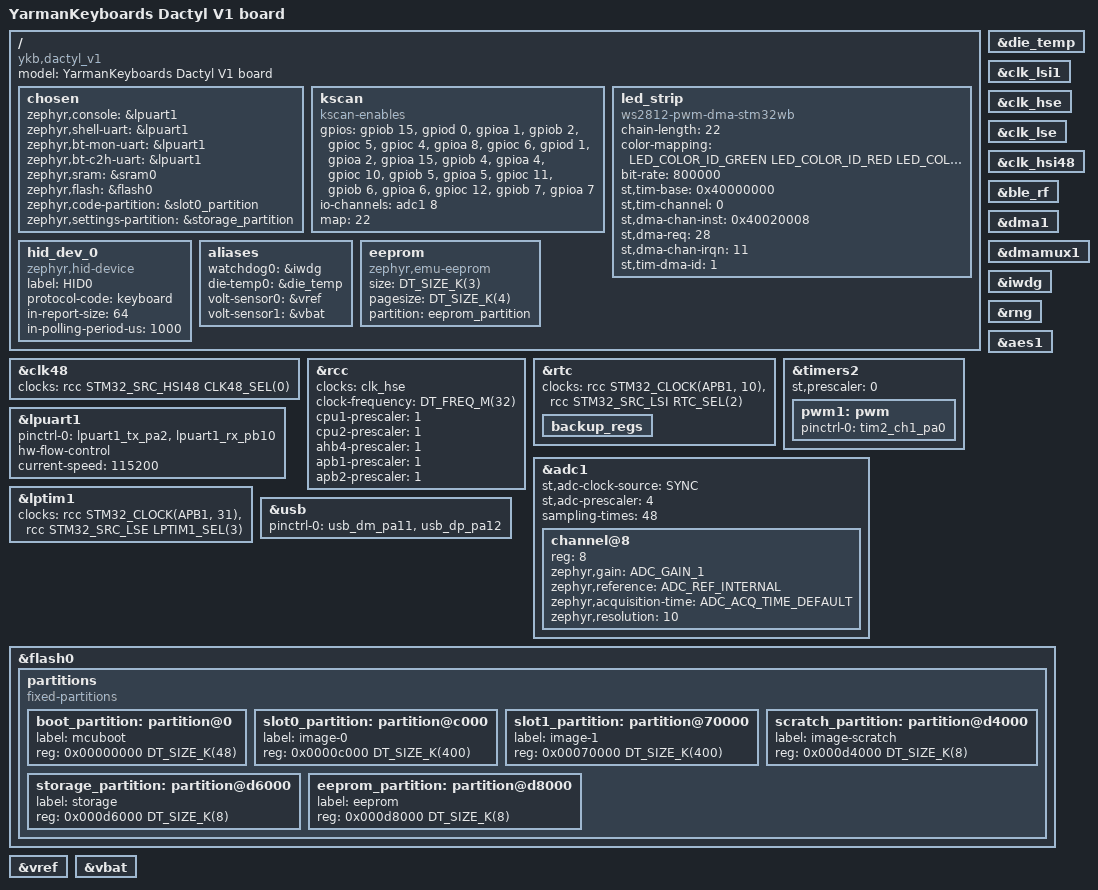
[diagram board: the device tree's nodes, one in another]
/dts-v1/;
#include <st/wb/stm32wb55Xg.dtsi>
#include <st/wb/stm32wb55rgvx-pinctrl.dtsi>
#include <zephyr/dt-bindings/input/input-event-codes.h>
#include <zephyr/dt-bindings/led/led.h>

/ {
	model = "YarmanKeyboards Dactyl V1 board";
	compatible = "ykb,dactyl_v1";

	chosen {
		zephyr,console = &lpuart1;
		zephyr,shell-uart = &lpuart1;
		zephyr,bt-mon-uart = &lpuart1;
		zephyr,bt-c2h-uart = &lpuart1;
		zephyr,sram = &sram0;
		zephyr,flash = &flash0;
		zephyr,code-partition = &slot0_partition;
        zephyr,settings-partition = &storage_partition;

        // ykb,backlight = &led_strip;
	};

    kscan: kscan {
        compatible = "kscan-enables";
        status = "okay";

        gpios = <&gpiob 15 GPIO_ACTIVE_HIGH>,
                <&gpiod 0 GPIO_ACTIVE_HIGH>,
                <&gpioa 1 GPIO_ACTIVE_HIGH>,
                <&gpiob 2 GPIO_ACTIVE_HIGH>,
                <&gpioc 5 GPIO_ACTIVE_HIGH>,
                <&gpioc 4 GPIO_ACTIVE_HIGH>,
                <&gpioa 8 GPIO_ACTIVE_HIGH>,
                <&gpioc 6 GPIO_ACTIVE_HIGH>,
                <&gpiod 1 GPIO_ACTIVE_HIGH>,
                <&gpioa 2 GPIO_ACTIVE_HIGH>,
                <&gpioa 15 GPIO_ACTIVE_HIGH>,
                <&gpiob 4 GPIO_ACTIVE_HIGH>,
                <&gpioa 4 GPIO_ACTIVE_HIGH>,
                <&gpioc 10 GPIO_ACTIVE_HIGH>,
                <&gpiob 5 GPIO_ACTIVE_HIGH>,
                <&gpioa 5 GPIO_ACTIVE_HIGH>,
                <&gpioc 11 GPIO_ACTIVE_HIGH>,
                <&gpiob 6 GPIO_ACTIVE_HIGH>,
                <&gpioa 6 GPIO_ACTIVE_HIGH>,
                <&gpioc 12 GPIO_ACTIVE_HIGH>,
                <&gpiob 7 GPIO_ACTIVE_HIGH>,
                <&gpioa 7 GPIO_ACTIVE_HIGH>;

        io-channels = <&adc1 8>;

        map = <22>;
    };

    led_strip: led_strip {
        compatible = "ws2812-pwm-dma-stm32wb";

        chain-length = <22>;
        color-mapping = <LED_COLOR_ID_GREEN
                         LED_COLOR_ID_RED
                         LED_COLOR_ID_BLUE>;

        bit-rate = <800000>; // 800Khz

        st,tim-base      = <0x40000000>;  // TIM2 base
        st,tim-channel   = <0>;           // TIM_CHANNEL_1
        st,dma-chan-inst = <0x40020008>;  // DMA1_Channel1 base
        st,dma-req       = <28>;          // TIM2_CH1_REQ
        st,dma-chan-irqn = <11>;          // DMA1_Channel1_IRQn
        st,tim-dma-id    = <1>;           // TIM_DMA_ID_CC1
    };

	hid_dev_0: hid_dev_0 {
		compatible = "zephyr,hid-device";
		label = "HID0";
		protocol-code = "keyboard";
		in-report-size = <64>;
		in-polling-period-us = <1000>;
	};

	aliases {
		watchdog0 = &iwdg;
		die-temp0 = &die_temp;
		volt-sensor0 = &vref;
		volt-sensor1 = &vbat;
	};

    eeprom: eeprom {
        compatible = "zephyr,emu-eeprom";
        size = <DT_SIZE_K(3)>;
        pagesize = <DT_SIZE_K(4)>;
        partition = <&eeprom_partition>;
    };
};

&die_temp {
	status = "okay";
};

&clk_lsi1 {
	status = "okay";
};

&clk_hse {
	status = "okay";
};

&clk_lse {
	status = "okay";
};

&clk_hsi48 {
	status = "okay";
};

&clk48 {
	/* Node is disabled by default as default source is HSI48 */
	/* To select another clock, enable the node */
	clocks = <&rcc STM32_SRC_HSI48 CLK48_SEL(0)>;
};

&ble_rf {
    status = "okay";
};

&rcc {
	clocks = <&clk_hse>;
	clock-frequency = <DT_FREQ_M(32)>;
	cpu1-prescaler = <1>;
	cpu2-prescaler = <1>;
	ahb4-prescaler = <1>;
	apb1-prescaler = <1>;
	apb2-prescaler = <1>;
};

//
// &i2c3 {
// 	pinctrl-0 = <&i2c3_scl_pc0 &i2c3_sda_pc1>;
// 	pinctrl-names = "default";
// 	status = "okay";
// 	clock-frequency = <I2C_BITRATE_FAST>;
// };

&rtc {
	clocks = <&rcc STM32_CLOCK(APB1, 10)>,
		 <&rcc STM32_SRC_LSI RTC_SEL(2)>;
	status = "okay";

	backup_regs {
		status = "okay";
	};
};

&timers2 {
	st,prescaler = <0>;
	status = "okay";

	pwm1: pwm {
		status = "okay";
		pinctrl-0 = <&tim2_ch1_pa0>;
		pinctrl-names = "default";
	};

};

&dma1 {
    status = "okay";
};

&dmamux1 {
    status = "okay";
};

&lpuart1 {
	pinctrl-0 = <&lpuart1_tx_pa2 &lpuart1_rx_pb10>;
	hw-flow-control;
	pinctrl-names = "default";
	current-speed = <115200>;
	status = "okay";
};

&adc1 {
	st,adc-clock-source = "SYNC";
	st,adc-prescaler = <4>;
    sampling-times = <48>;
	status = "okay";

    #address-cells = <1>;
    #size-cells = <0>;

    channel@8 {
        reg = <8>;
        zephyr,gain = "ADC_GAIN_1";
        zephyr,reference = "ADC_REF_INTERNAL";
        zephyr,acquisition-time = <ADC_ACQ_TIME_DEFAULT>;
        zephyr,resolution = <10>;
    };

};

&iwdg {
	status = "okay";
};

stm32_lp_tick_source: &lptim1 {
	clocks = <&rcc STM32_CLOCK(APB1, 31)>,
		 <&rcc STM32_SRC_LSE LPTIM1_SEL(3)>;
	status = "okay";
};

zephyr_udc0: &usb {
	status = "okay";
	pinctrl-0 = <&usb_dm_pa11 &usb_dp_pa12>;
	pinctrl-names = "default";
};

&rng {
	status = "okay";
};

&aes1 {
	status = "okay";
};

&flash0 {
	partitions {
		compatible = "fixed-partitions";
		#address-cells = <1>;
		#size-cells = <1>;

		/*
		 * Configure partitions while leaving space for M0 BLE f/w
		 * Since STM32WBCube release V1.13.2, only _HCIOnly_ f/w are supported.
		 * These FW are expected to be located not before 0x080DB000
		 * Current partition is using the first 876K of the flash for M4
		 */

		boot_partition: partition@0 {
			label = "mcuboot";
			reg = <0x00000000 DT_SIZE_K(48)>;
		};

		slot0_partition: partition@c000 {
			label = "image-0";
			reg = <0x0000c000 DT_SIZE_K(400)>;
		};

		slot1_partition: partition@70000 {
			label = "image-1";
			reg = <0x00070000 DT_SIZE_K(400)>;
		};

		scratch_partition: partition@d4000 {
			label = "image-scratch";
			reg = <0x000d4000 DT_SIZE_K(8)>;
		};

        storage_partition: partition@d6000 {
            label = "storage";
            reg = <0x000d6000 DT_SIZE_K(8)>;
        };

		eeprom_partition: partition@d8000 {
			label = "eeprom";
			reg = <0x000d8000 DT_SIZE_K(8)>;
		};
	};
};

&vref {
	status = "okay";
};

&vbat {
	status = "okay";
};
